# ESP32-C6 register map
Vendor: ESPRESSIF SYSTEMS (SHANGHAI) CO., LTD.; Series: ESP32 C-Series; File version: 2
CPU: RV32IMC r0p0, little endian, no MPU, no FPU, 4 interrupt priority bits
Address unit: 32 bits
Registers are 32-bit, read-write, reset 0x0 unless marked. A register's access mark holds for its fields unless they carry their own. Offsets are from the block's base; [hi:lo] are bit positions; {n}, {i} and the like mark numbered series.

## EXTMEM (part 1 of 2) — External Memory
Base 0x600C8000
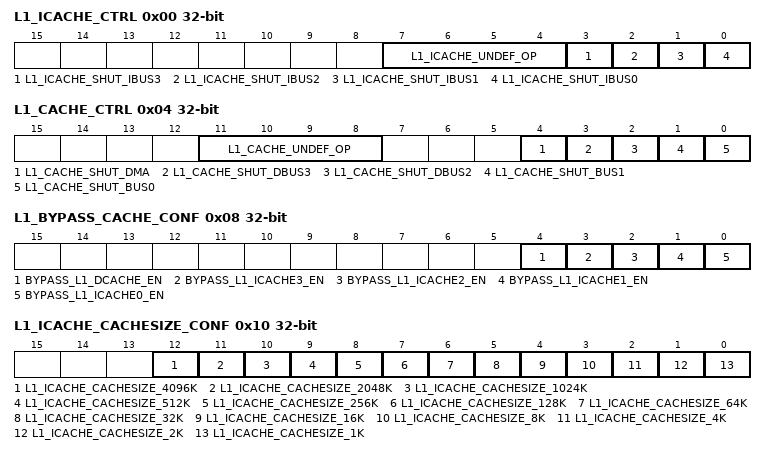
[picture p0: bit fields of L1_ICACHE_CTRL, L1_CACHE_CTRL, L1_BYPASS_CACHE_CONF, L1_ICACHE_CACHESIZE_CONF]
0x00 L1_ICACHE_CTRL ro — L1 instruction Cache(L1-ICache) control register
  [7:4] L1_ICACHE_UNDEF_OP — Reserved
  [3] L1_ICACHE_SHUT_IBUS3 — Reserved
  [2] L1_ICACHE_SHUT_IBUS2 — Reserved
  [1] L1_ICACHE_SHUT_IBUS1 — The bit is used to disable core1 ibus access L1-ICache, 0: enable, 1: disable
  [0] L1_ICACHE_SHUT_IBUS0 — The bit is used to disable core0 ibus access L1-ICache, 0: enable, 1: disable
0x04 L1_CACHE_CTRL access per field — L1 data Cache(L1-Cache) control register
  [11:8] L1_CACHE_UNDEF_OP rw — Reserved
  [4] L1_CACHE_SHUT_DMA ro — The bit is used to disable DMA access L1-Cache, 0: enable, 1: disable
  [3] L1_CACHE_SHUT_DBUS3 ro — Reserved
  [2] L1_CACHE_SHUT_DBUS2 ro — Reserved
  [1] L1_CACHE_SHUT_BUS1 rw — The bit is used to disable core1 dbus access L1-Cache, 0: enable, 1: disable
  [0] L1_CACHE_SHUT_BUS0 rw — The bit is used to disable core0 dbus access L1-Cache, 0: enable, 1: disable
0x08 L1_BYPASS_CACHE_CONF ro — Bypass Cache configure register
  [4] BYPASS_L1_DCACHE_EN — The bit is used to enable bypass L1-DCache. 0: disable bypass, 1: enable bypass.
  [3] BYPASS_L1_ICACHE3_EN — Reserved
  [2] BYPASS_L1_ICACHE2_EN — Reserved
  [1] BYPASS_L1_ICACHE1_EN — The bit is used to enable bypass L1-ICache1. 0: disable bypass, 1: enable bypass.
  [0] BYPASS_L1_ICACHE0_EN — The bit is used to enable bypass L1-ICache0. 0: disable bypass, 1: enable bypass.
0x0C L1_CACHE_ATOMIC_CONF ro — L1 Cache atomic feature configure register
  [0] L1_CACHE_ATOMIC_EN — The bit is used to enable atomic feature on L1-Cache when multiple cores access L1-Cache. 1: disable, 1: enable.
0x10 L1_ICACHE_CACHESIZE_CONF ro — L1 instruction Cache CacheSize mode configure register
  [12] L1_ICACHE_CACHESIZE_4096K — The field is used to configure cachesize of L1-ICache as 4096k bytes. This field and all other fields within this register is onehot.
  [11] L1_ICACHE_CACHESIZE_2048K — The field is used to configure cachesize of L1-ICache as 2048k bytes. This field and all other fields within this register is onehot.
  [10] L1_ICACHE_CACHESIZE_1024K — The field is used to configure cachesize of L1-ICache as 1024k bytes. This field and all other fields within this register is onehot.
  [9] L1_ICACHE_CACHESIZE_512K — The field is used to configure cachesize of L1-ICache as 512k bytes. This field and all other fields within this register is onehot.
  [8] L1_ICACHE_CACHESIZE_256K — The field is used to configure cachesize of L1-ICache as 256k bytes. This field and all other fields within this register is onehot.
  [7] L1_ICACHE_CACHESIZE_128K — The field is used to configure cachesize of L1-ICache as 128k bytes. This field and all other fields within this register is onehot.
  [6] L1_ICACHE_CACHESIZE_64K — The field is used to configure cachesize of L1-ICache as 64k bytes. This field and all other fields within this register is onehot.
  [5] L1_ICACHE_CACHESIZE_32K — The field is used to configure cachesize of L1-ICache as 32k bytes. This field and all other fields within this register is onehot.
  [4] L1_ICACHE_CACHESIZE_16K — The field is used to configure cachesize of L1-ICache as 16k bytes. This field and all other fields within this register is onehot.
  [3] L1_ICACHE_CACHESIZE_8K — The field is used to configure cachesize of L1-ICache as 8k bytes. This field and all other fields within this register is onehot.
  [2] L1_ICACHE_CACHESIZE_4K — The field is used to configure cachesize of L1-ICache as 4k bytes. This field and all other fields within this register is onehot.
  [1] L1_ICACHE_CACHESIZE_2K — The field is used to configure cachesize of L1-ICache as 2k bytes. This field and all other fields within this register is onehot.
  [0] L1_ICACHE_CACHESIZE_1K — The field is used to configure cachesize of L1-ICache as 1k bytes. This field and all other fields within this register is onehot.
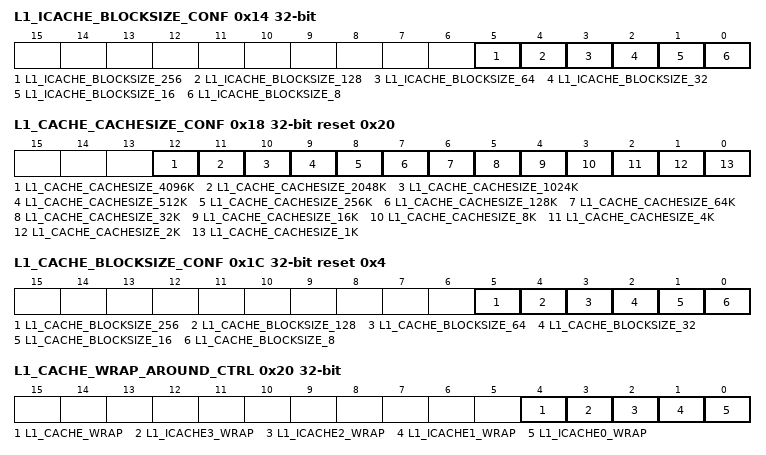
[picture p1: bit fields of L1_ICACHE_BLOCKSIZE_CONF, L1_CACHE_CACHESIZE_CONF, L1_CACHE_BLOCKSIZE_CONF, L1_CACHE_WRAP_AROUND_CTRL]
0x14 L1_ICACHE_BLOCKSIZE_CONF ro — L1 instruction Cache BlockSize mode configure register
  [5] L1_ICACHE_BLOCKSIZE_256 — The field is used to configureblocksize of L1-ICache as 256 bytes. This field and all other fields within this register is onehot.
  [4] L1_ICACHE_BLOCKSIZE_128 — The field is used to configureblocksize of L1-ICache as 128 bytes. This field and all other fields within this register is onehot.
  [3] L1_ICACHE_BLOCKSIZE_64 — The field is used to configureblocksize of L1-ICache as 64 bytes. This field and all other fields within this register is onehot.
  [2] L1_ICACHE_BLOCKSIZE_32 — The field is used to configureblocksize of L1-ICache as 32 bytes. This field and all other fields within this register is onehot.
  [1] L1_ICACHE_BLOCKSIZE_16 — The field is used to configureblocksize of L1-ICache as 16 bytes. This field and all other fields within this register is onehot.
  [0] L1_ICACHE_BLOCKSIZE_8 — The field is used to configureblocksize of L1-ICache as 8 bytes. This field and all other fields within this register is onehot.
0x18 L1_CACHE_CACHESIZE_CONF ro reset 0x20 — L1 data Cache CacheSize mode configure register
  [12] L1_CACHE_CACHESIZE_4096K — The field is used to configure cachesize of L1-Cache as 4096k bytes. This field and all other fields within this register is onehot.
  [11] L1_CACHE_CACHESIZE_2048K — The field is used to configure cachesize of L1-Cache as 2048k bytes. This field and all other fields within this register is onehot.
  [10] L1_CACHE_CACHESIZE_1024K — The field is used to configure cachesize of L1-Cache as 1024k bytes. This field and all other fields within this register is onehot.
  [9] L1_CACHE_CACHESIZE_512K — The field is used to configure cachesize of L1-Cache as 512k bytes. This field and all other fields within this register is onehot.
  [8] L1_CACHE_CACHESIZE_256K — The field is used to configure cachesize of L1-Cache as 256k bytes. This field and all other fields within this register is onehot.
  [7] L1_CACHE_CACHESIZE_128K — The field is used to configure cachesize of L1-Cache as 128k bytes. This field and all other fields within this register is onehot.
  [6] L1_CACHE_CACHESIZE_64K — The field is used to configure cachesize of L1-Cache as 64k bytes. This field and all other fields within this register is onehot.
  [5] L1_CACHE_CACHESIZE_32K — The field is used to configure cachesize of L1-Cache as 32k bytes. This field and all other fields within this register is onehot.
  [4] L1_CACHE_CACHESIZE_16K — The field is used to configure cachesize of L1-Cache as 16k bytes. This field and all other fields within this register is onehot.
  [3] L1_CACHE_CACHESIZE_8K — The field is used to configure cachesize of L1-Cache as 8k bytes. This field and all other fields within this register is onehot.
  [2] L1_CACHE_CACHESIZE_4K — The field is used to configure cachesize of L1-Cache as 4k bytes. This field and all other fields within this register is onehot.
  [1] L1_CACHE_CACHESIZE_2K — The field is used to configure cachesize of L1-Cache as 2k bytes. This field and all other fields within this register is onehot.
  [0] L1_CACHE_CACHESIZE_1K — The field is used to configure cachesize of L1-Cache as 1k bytes. This field and all other fields within this register is onehot.
0x1C L1_CACHE_BLOCKSIZE_CONF ro reset 0x4 — L1 data Cache BlockSize mode configure register
  [5] L1_CACHE_BLOCKSIZE_256 — The field is used to configureblocksize of L1-DCache as 256 bytes. This field and all other fields within this register is onehot.
  [4] L1_CACHE_BLOCKSIZE_128 — The field is used to configureblocksize of L1-DCache as 128 bytes. This field and all other fields within this register is onehot.
  [3] L1_CACHE_BLOCKSIZE_64 — The field is used to configureblocksize of L1-DCache as 64 bytes. This field and all other fields within this register is onehot.
  [2] L1_CACHE_BLOCKSIZE_32 — The field is used to configureblocksize of L1-DCache as 32 bytes. This field and all other fields within this register is onehot.
  [1] L1_CACHE_BLOCKSIZE_16 — The field is used to configureblocksize of L1-DCache as 16 bytes. This field and all other fields within this register is onehot.
  [0] L1_CACHE_BLOCKSIZE_8 — The field is used to configureblocksize of L1-DCache as 8 bytes. This field and all other fields within this register is onehot.
0x20 L1_CACHE_WRAP_AROUND_CTRL access per field — Cache wrap around control register
  [4] L1_CACHE_WRAP rw — Set this bit as 1 to enable L1-DCache wrap around mode.
  [3] L1_ICACHE3_WRAP ro — Reserved
  [2] L1_ICACHE2_WRAP ro — Reserved
  [1] L1_ICACHE1_WRAP ro — Set this bit as 1 to enable L1-ICache1 wrap around mode.
  [0] L1_ICACHE0_WRAP ro — Set this bit as 1 to enable L1-ICache0 wrap around mode.
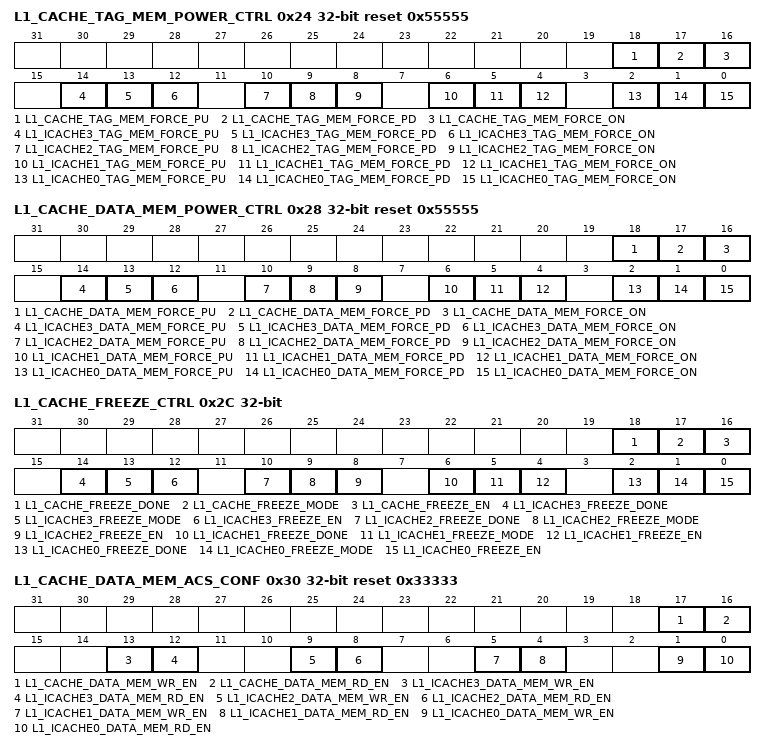
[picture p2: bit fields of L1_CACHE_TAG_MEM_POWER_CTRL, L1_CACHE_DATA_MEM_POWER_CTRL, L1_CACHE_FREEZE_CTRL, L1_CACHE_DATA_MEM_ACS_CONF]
0x24 L1_CACHE_TAG_MEM_POWER_CTRL access per field reset 0x55555 — Cache tag memory power control register
  [18] L1_CACHE_TAG_MEM_FORCE_PU rw — The bit is used to power L1-Cache tag memory up. 0: follow rtc_lslp, 1: power up
  [17] L1_CACHE_TAG_MEM_FORCE_PD rw — The bit is used to power L1-Cache tag memory down. 0: follow rtc_lslp, 1: power down
  [16] L1_CACHE_TAG_MEM_FORCE_ON rw — The bit is used to close clock gating of L1-Cache tag memory. 1: close gating, 0: open clock gating.
  [14] L1_ICACHE3_TAG_MEM_FORCE_PU ro — Reserved
  [13] L1_ICACHE3_TAG_MEM_FORCE_PD ro — Reserved
  [12] L1_ICACHE3_TAG_MEM_FORCE_ON ro — Reserved
  [10] L1_ICACHE2_TAG_MEM_FORCE_PU ro — Reserved
  [9] L1_ICACHE2_TAG_MEM_FORCE_PD ro — Reserved
  [8] L1_ICACHE2_TAG_MEM_FORCE_ON ro — Reserved
  [6] L1_ICACHE1_TAG_MEM_FORCE_PU ro — The bit is used to power L1-ICache1 tag memory up. 0: follow rtc_lslp, 1: power up
  [5] L1_ICACHE1_TAG_MEM_FORCE_PD ro — The bit is used to power L1-ICache1 tag memory down. 0: follow rtc_lslp, 1: power down
  [4] L1_ICACHE1_TAG_MEM_FORCE_ON ro — The bit is used to close clock gating of L1-ICache1 tag memory. 1: close gating, 0: open clock gating.
  [2] L1_ICACHE0_TAG_MEM_FORCE_PU ro — The bit is used to power L1-ICache0 tag memory up. 0: follow rtc_lslp, 1: power up
  [1] L1_ICACHE0_TAG_MEM_FORCE_PD ro — The bit is used to power L1-ICache0 tag memory down. 0: follow rtc_lslp, 1: power down
  [0] L1_ICACHE0_TAG_MEM_FORCE_ON ro — The bit is used to close clock gating of L1-ICache0 tag memory. 1: close gating, 0: open clock gating.
0x28 L1_CACHE_DATA_MEM_POWER_CTRL access per field reset 0x55555 — Cache data memory power control register
  [18] L1_CACHE_DATA_MEM_FORCE_PU rw — The bit is used to power L1-Cache data memory up. 0: follow rtc_lslp, 1: power up
  [17] L1_CACHE_DATA_MEM_FORCE_PD rw — The bit is used to power L1-Cache data memory down. 0: follow rtc_lslp, 1: power down
  [16] L1_CACHE_DATA_MEM_FORCE_ON rw — The bit is used to close clock gating of L1-Cache data memory. 1: close gating, 0: open clock gating.
  [14] L1_ICACHE3_DATA_MEM_FORCE_PU ro — Reserved
  [13] L1_ICACHE3_DATA_MEM_FORCE_PD ro — Reserved
  [12] L1_ICACHE3_DATA_MEM_FORCE_ON ro — Reserved
  [10] L1_ICACHE2_DATA_MEM_FORCE_PU ro — Reserved
  [9] L1_ICACHE2_DATA_MEM_FORCE_PD ro — Reserved
  [8] L1_ICACHE2_DATA_MEM_FORCE_ON ro — Reserved
  [6] L1_ICACHE1_DATA_MEM_FORCE_PU ro — The bit is used to power L1-ICache1 data memory up. 0: follow rtc_lslp, 1: power up
  [5] L1_ICACHE1_DATA_MEM_FORCE_PD ro — The bit is used to power L1-ICache1 data memory down. 0: follow rtc_lslp, 1: power down
  [4] L1_ICACHE1_DATA_MEM_FORCE_ON ro — The bit is used to close clock gating of L1-ICache1 data memory. 1: close gating, 0: open clock gating.
  [2] L1_ICACHE0_DATA_MEM_FORCE_PU ro — The bit is used to power L1-ICache0 data memory up. 0: follow rtc_lslp, 1: power up
  [1] L1_ICACHE0_DATA_MEM_FORCE_PD ro — The bit is used to power L1-ICache0 data memory down. 0: follow rtc_lslp, 1: power down
  [0] L1_ICACHE0_DATA_MEM_FORCE_ON ro — The bit is used to close clock gating of L1-ICache0 data memory. 1: close gating, 0: open clock gating.
0x2C L1_CACHE_FREEZE_CTRL access per field — Cache Freeze control register
  [18] L1_CACHE_FREEZE_DONE ro — The bit is used to indicate whether freeze operation on L1-Cache is finished or not. 0: not finished. 1: finished.
  [17] L1_CACHE_FREEZE_MODE rw — The bit is used to configure mode of freeze operation L1-Cache. 0: a miss-access will not stuck. 1: a miss-access will stuck.
  [16] L1_CACHE_FREEZE_EN rw — The bit is used to enable freeze operation on L1-Cache. It can be cleared by software.
  [14] L1_ICACHE3_FREEZE_DONE ro — Reserved
  [13] L1_ICACHE3_FREEZE_MODE ro — Reserved
  [12] L1_ICACHE3_FREEZE_EN ro — Reserved
  [10] L1_ICACHE2_FREEZE_DONE ro — Reserved
  [9] L1_ICACHE2_FREEZE_MODE ro — Reserved
  [8] L1_ICACHE2_FREEZE_EN ro — Reserved
  [6] L1_ICACHE1_FREEZE_DONE ro — The bit is used to indicate whether freeze operation on L1-ICache1 is finished or not. 0: not finished. 1: finished.
  [5] L1_ICACHE1_FREEZE_MODE ro — The bit is used to configure mode of freeze operation L1-ICache1. 0: a miss-access will not stuck. 1: a miss-access will stuck.
  [4] L1_ICACHE1_FREEZE_EN ro — The bit is used to enable freeze operation on L1-ICache1. It can be cleared by software.
  [2] L1_ICACHE0_FREEZE_DONE ro — The bit is used to indicate whether freeze operation on L1-ICache0 is finished or not. 0: not finished. 1: finished.
  [1] L1_ICACHE0_FREEZE_MODE ro — The bit is used to configure mode of freeze operation L1-ICache0. 0: a miss-access will not stuck. 1: a miss-access will stuck.
  [0] L1_ICACHE0_FREEZE_EN ro — The bit is used to enable freeze operation on L1-ICache0. It can be cleared by software.
0x30 L1_CACHE_DATA_MEM_ACS_CONF access per field reset 0x33333 — Cache data memory access configure register
  [17] L1_CACHE_DATA_MEM_WR_EN rw — The bit is used to enable config-bus write L1-Cache data memoryory. 0: disable, 1: enable.
  [16] L1_CACHE_DATA_MEM_RD_EN rw — The bit is used to enable config-bus read L1-Cache data memoryory. 0: disable, 1: enable.
  [13] L1_ICACHE3_DATA_MEM_WR_EN ro — Reserved
  [12] L1_ICACHE3_DATA_MEM_RD_EN ro — Reserved
  [9] L1_ICACHE2_DATA_MEM_WR_EN ro — Reserved
  [8] L1_ICACHE2_DATA_MEM_RD_EN ro — Reserved
  [5] L1_ICACHE1_DATA_MEM_WR_EN ro — The bit is used to enable config-bus write L1-ICache1 data memoryory. 0: disable, 1: enable.
  [4] L1_ICACHE1_DATA_MEM_RD_EN ro — The bit is used to enable config-bus read L1-ICache1 data memoryory. 0: disable, 1: enable.
  [1] L1_ICACHE0_DATA_MEM_WR_EN ro — The bit is used to enable config-bus write L1-ICache0 data memoryory. 0: disable, 1: enable.
  [0] L1_ICACHE0_DATA_MEM_RD_EN ro — The bit is used to enable config-bus read L1-ICache0 data memoryory. 0: disable, 1: enable.
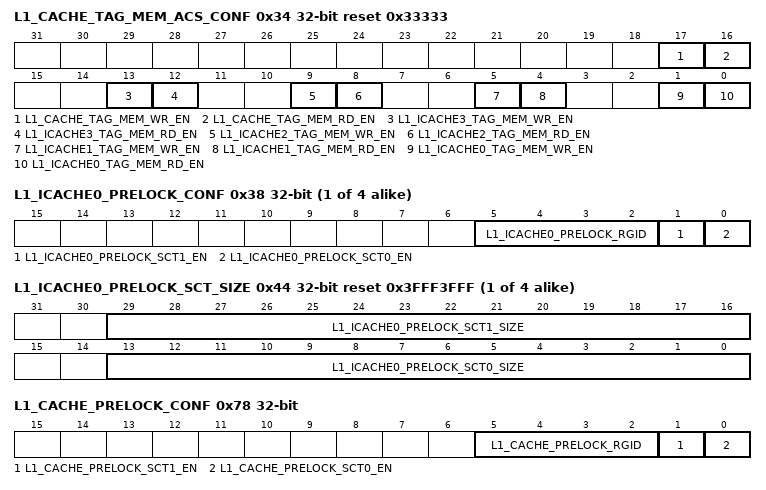
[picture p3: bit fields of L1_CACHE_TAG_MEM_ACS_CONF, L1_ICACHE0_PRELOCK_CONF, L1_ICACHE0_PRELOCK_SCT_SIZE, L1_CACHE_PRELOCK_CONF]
0x34 L1_CACHE_TAG_MEM_ACS_CONF access per field reset 0x33333 — Cache tag memory access configure register
  [17] L1_CACHE_TAG_MEM_WR_EN rw — The bit is used to enable config-bus write L1-Cache tag memoryory. 0: disable, 1: enable.
  [16] L1_CACHE_TAG_MEM_RD_EN rw — The bit is used to enable config-bus read L1-Cache tag memoryory. 0: disable, 1: enable.
  [13] L1_ICACHE3_TAG_MEM_WR_EN ro — Reserved
  [12] L1_ICACHE3_TAG_MEM_RD_EN ro — Reserved
  [9] L1_ICACHE2_TAG_MEM_WR_EN ro — Reserved
  [8] L1_ICACHE2_TAG_MEM_RD_EN ro — Reserved
  [5] L1_ICACHE1_TAG_MEM_WR_EN ro — The bit is used to enable config-bus write L1-ICache1 tag memoryory. 0: disable, 1: enable.
  [4] L1_ICACHE1_TAG_MEM_RD_EN ro — The bit is used to enable config-bus read L1-ICache1 tag memoryory. 0: disable, 1: enable.
  [1] L1_ICACHE0_TAG_MEM_WR_EN ro — The bit is used to enable config-bus write L1-ICache0 tag memoryory. 0: disable, 1: enable.
  [0] L1_ICACHE0_TAG_MEM_RD_EN ro — The bit is used to enable config-bus read L1-ICache0 tag memoryory. 0: disable, 1: enable.
{0x38+0x10*i} L1_ICACHE{i}_PRELOCK_CONF ro (i=0..3) — L1 instruction Cache {i} prelock configure register
  [5:2] L1_ICACHE{i}_PRELOCK_RGID — The bit is used to set the gid of l1 icache{i} prelock.
  [1] L1_ICACHE{i}_PRELOCK_SCT1_EN — The bit is used to enable the second section of prelock function on L1-ICache{i}.
  [0] L1_ICACHE{i}_PRELOCK_SCT0_EN — The bit is used to enable the first section of prelock function on L1-ICache{i}.
{0x3C+0x10*i} L1_ICACHE{i}_PRELOCK_SCT0_ADDR ro (i=0..3) — L1 instruction Cache {i} prelock section0 address configure register
  [31:0] L1_ICACHE{i}_PRELOCK_SCT0_ADDR — Those bits are used to configure the start virtual address of the first section of prelock on L1-ICache{i}, which should be used together with L1_ICACHE{i}_PRELOCK_SCT0_SIZE_REG
{0x40+0x10*i} L1_ICACHE{i}_PRELOCK_SCT1_ADDR ro (i=0..3) — L1 instruction Cache {i} prelock section1 address configure register
  [31:0] L1_ICACHE{i}_PRELOCK_SCT1_ADDR — Those bits are used to configure the start virtual address of the second section of prelock on L1-ICache{i}, which should be used together with L1_ICACHE{i}_PRELOCK_SCT1_SIZE_REG
{0x44+0x10*i} L1_ICACHE{i}_PRELOCK_SCT_SIZE ro reset 0x3FFF3FFF (i=0..3) — L1 instruction Cache {i} prelock section size configure register
  [29:16] L1_ICACHE{i}_PRELOCK_SCT1_SIZE — Those bits are used to configure the size of the second section of prelock on L1-ICache{i}, which should be used together with L1_ICACHE{i}_PRELOCK_SCT1_ADDR_REG
  [13:0] L1_ICACHE{i}_PRELOCK_SCT0_SIZE — Those bits are used to configure the size of the first section of prelock on L1-ICache{i}, which should be used together with L1_ICACHE{i}_PRELOCK_SCT0_ADDR_REG
0x78 L1_CACHE_PRELOCK_CONF access per field — L1 Cache prelock configure register
  [5:2] L1_CACHE_PRELOCK_RGID ro — The bit is used to set the gid of l1 cache prelock.
  [1] L1_CACHE_PRELOCK_SCT1_EN rw — The bit is used to enable the second section of prelock function on L1-Cache.
  [0] L1_CACHE_PRELOCK_SCT0_EN rw — The bit is used to enable the first section of prelock function on L1-Cache.
0x7C L1_CACHE_PRELOCK_SCT0_ADDR — L1 Cache prelock section0 address configure register
  [31:0] L1_CACHE_PRELOCK_SCT0_ADDR — Those bits are used to configure the start virtual address of the first section of prelock on L1-Cache, which should be used together with L1_CACHE_PRELOCK_SCT0_SIZE_REG
0x80 L1_DCACHE_PRELOCK_SCT1_ADDR — L1 Cache prelock section1 address configure register
  [31:0] L1_CACHE_PRELOCK_SCT1_ADDR — Those bits are used to configure the start virtual address of the second section of prelock on L1-Cache, which should be used together with L1_CACHE_PRELOCK_SCT1_SIZE_REG
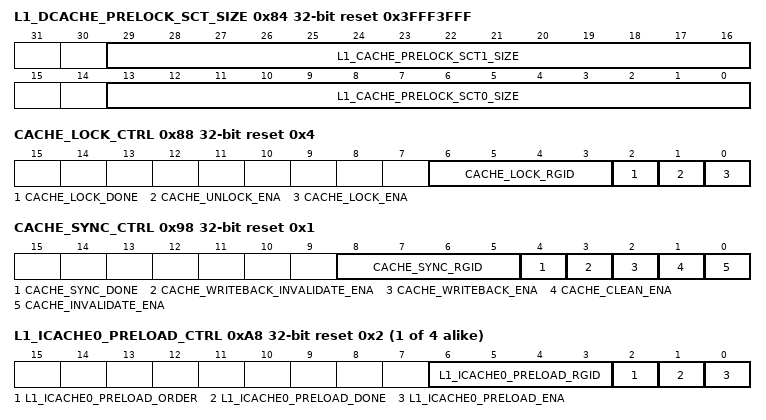
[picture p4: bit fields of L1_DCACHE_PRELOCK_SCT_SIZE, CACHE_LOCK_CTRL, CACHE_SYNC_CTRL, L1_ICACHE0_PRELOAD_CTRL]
0x84 L1_DCACHE_PRELOCK_SCT_SIZE reset 0x3FFF3FFF — L1 Cache prelock section size configure register
  [29:16] L1_CACHE_PRELOCK_SCT1_SIZE — Those bits are used to configure the size of the second section of prelock on L1-Cache, which should be used together with L1_CACHE_PRELOCK_SCT1_ADDR_REG
  [13:0] L1_CACHE_PRELOCK_SCT0_SIZE — Those bits are used to configure the size of the first section of prelock on L1-Cache, which should be used together with L1_CACHE_PRELOCK_SCT0_ADDR_REG
0x88 CACHE_LOCK_CTRL access per field reset 0x4 — Lock-class (manual lock) operation control register
  [6:3] CACHE_LOCK_RGID ro — The bit is used to set the gid of cache lock/unlock.
  [2] CACHE_LOCK_DONE ro — The bit is used to indicate whether unlock/lock operation is finished or not. 0: not finished. 1: finished.
  [1] CACHE_UNLOCK_ENA rw — The bit is used to enable unlock operation. It will be cleared by hardware after unlock operation done
  [0] CACHE_LOCK_ENA rw — The bit is used to enable lock operation. It will be cleared by hardware after lock operation done
0x8C CACHE_LOCK_MAP — Lock (manual lock) map configure register
  [5:0] CACHE_LOCK_MAP — Those bits are used to indicate which caches in the two-level cache structure will apply this lock/unlock operation. [4]: L1-Cache
0x90 CACHE_LOCK_ADDR — Lock (manual lock) address configure register
  [31:0] CACHE_LOCK_ADDR — Those bits are used to configure the start virtual address of the lock/unlock operation, which should be used together with CACHE_LOCK_SIZE_REG
0x94 CACHE_LOCK_SIZE — Lock (manual lock) size configure register
  [15:0] CACHE_LOCK_SIZE — Those bits are used to configure the size of the lock/unlock operation, which should be used together with CACHE_LOCK_ADDR_REG
0x98 CACHE_SYNC_CTRL access per field reset 0x1 — Sync-class operation control register
  [8:5] CACHE_SYNC_RGID ro — The bit is used to set the gid of cache sync operation (invalidate, clean, writeback, writeback_invalidate)
  [4] CACHE_SYNC_DONE ro — The bit is used to indicate whether sync operation (invalidate, clean, writeback, writeback_invalidate) is finished or not. 0: not finished. 1: finished.
  [3] CACHE_WRITEBACK_INVALIDATE_ENA rw — The bit is used to enable writeback-invalidate operation. It will be cleared by hardware after writeback-invalidate operation done. Note that this bit and the other sync-bits (invalidate_ena, clean_ena, writeback_ena) are mutually exclusive, that is, those bits can not be set to 1 at the same time.
  [2] CACHE_WRITEBACK_ENA rw — The bit is used to enable writeback operation. It will be cleared by hardware after writeback operation done. Note that this bit and the other sync-bits (invalidate_ena, clean_ena, writeback_invalidate_ena) are mutually exclusive, that is, those bits can not be set to 1 at the same time.
  [1] CACHE_CLEAN_ENA rw — The bit is used to enable clean operation. It will be cleared by hardware after clean operation done. Note that this bit and the other sync-bits (invalidate_ena, writeback_ena, writeback_invalidate_ena) are mutually exclusive, that is, those bits can not be set to 1 at the same time.
  [0] CACHE_INVALIDATE_ENA rw — The bit is used to enable invalidate operation. It will be cleared by hardware after invalidate operation done. Note that this bit and the other sync-bits (clean_ena, writeback_ena, writeback_invalidate_ena) are mutually exclusive, that is, those bits can not be set to 1 at the same time.
0x9C CACHE_SYNC_MAP reset 0x3F — Sync map configure register
  [5:0] CACHE_SYNC_MAP — Those bits are used to indicate which caches in the two-level cache structure will apply the sync operation. [4]: L1-Cache
0xA0 CACHE_SYNC_ADDR — Sync address configure register
  [31:0] CACHE_SYNC_ADDR — Those bits are used to configure the start virtual address of the sync operation, which should be used together with CACHE_SYNC_SIZE_REG
0xA4 CACHE_SYNC_SIZE — Sync size configure register
  [23:0] CACHE_SYNC_SIZE — Those bits are used to configure the size of the sync operation, which should be used together with CACHE_SYNC_ADDR_REG
{0xA8+0xC*i} L1_ICACHE{i}_PRELOAD_CTRL access per field reset 0x2 (i=0..3) — L1 instruction Cache {i} preload-operation control register
  [6:3] L1_ICACHE{i}_PRELOAD_RGID ro — The bit is used to set the gid of l1 icache{i} preload.
  [2] L1_ICACHE{i}_PRELOAD_ORDER ro — The bit is used to configure the direction of preload operation. 0: ascending, 1: descending.
  [1] L1_ICACHE{i}_PRELOAD_DONE ro — The bit is used to indicate whether preload operation is finished or not. 0: not finished. 1: finished.
  [0] L1_ICACHE{i}_PRELOAD_ENA rw — The bit is used to enable preload operation on L1-ICache{i}. It will be cleared by hardware automatically after preload operation is done.
{0xAC+0xC*i} L1_ICACHE{i}_PRELOAD_ADDR ro (i=0..3) — L1 instruction Cache {i} preload address configure register
  [31:0] L1_ICACHE{i}_PRELOAD_ADDR — Those bits are used to configure the start virtual address of preload on L1-ICache{i}, which should be used together with L1_ICACHE{i}_PRELOAD_SIZE_REG
{0xB0+0xC*i} L1_ICACHE{i}_PRELOAD_SIZE ro (i=0..3) — L1 instruction Cache {i} preload size configure register
  [13:0] L1_ICACHE{i}_PRELOAD_SIZE — Those bits are used to configure the size of the first section of prelock on L1-ICache{i}, which should be used together with L1_ICACHE{i}_PRELOAD_ADDR_REG
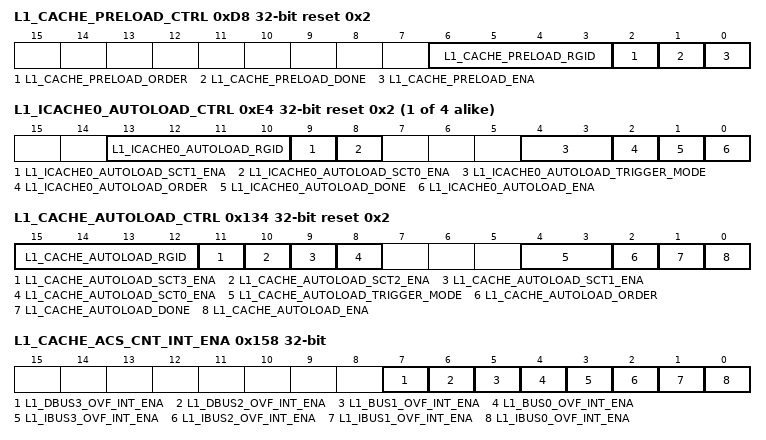
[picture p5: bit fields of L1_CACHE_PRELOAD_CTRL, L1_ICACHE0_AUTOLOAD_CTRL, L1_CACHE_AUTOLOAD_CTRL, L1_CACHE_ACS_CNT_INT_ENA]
0xD8 L1_CACHE_PRELOAD_CTRL access per field reset 0x2 — L1 Cache preload-operation control register
  [6:3] L1_CACHE_PRELOAD_RGID ro — The bit is used to set the gid of l1 cache preload.
  [2] L1_CACHE_PRELOAD_ORDER rw — The bit is used to configure the direction of preload operation. 0: ascending, 1: descending.
  [1] L1_CACHE_PRELOAD_DONE ro — The bit is used to indicate whether preload operation is finished or not. 0: not finished. 1: finished.
  [0] L1_CACHE_PRELOAD_ENA rw — The bit is used to enable preload operation on L1-Cache. It will be cleared by hardware automatically after preload operation is done.
0xDC L1_DCACHE_PRELOAD_ADDR — L1 Cache preload address configure register
  [31:0] L1_CACHE_PRELOAD_ADDR — Those bits are used to configure the start virtual address of preload on L1-Cache, which should be used together with L1_CACHE_PRELOAD_SIZE_REG
0xE0 L1_DCACHE_PRELOAD_SIZE — L1 Cache preload size configure register
  [13:0] L1_CACHE_PRELOAD_SIZE — Those bits are used to configure the size of the first section of prelock on L1-Cache, which should be used together with L1_CACHE_PRELOAD_ADDR_REG
{0xE4+0x14*i} L1_ICACHE{i}_AUTOLOAD_CTRL ro reset 0x2 (i=0..3) — L1 instruction Cache {i} autoload-operation control register
  [13:10] L1_ICACHE{i}_AUTOLOAD_RGID — The bit is used to set the gid of l1 icache{i} autoload.
  [9] L1_ICACHE{i}_AUTOLOAD_SCT1_ENA — The bit is used to enable the second section for autoload operation on L1-ICache{i}.
  [8] L1_ICACHE{i}_AUTOLOAD_SCT0_ENA — The bit is used to enable the first section for autoload operation on L1-ICache{i}.
  [4:3] L1_ICACHE{i}_AUTOLOAD_TRIGGER_MODE — The field is used to configure trigger mode of autoload operation on L1-ICache{i}. 0/3: miss-trigger, 1: hit-trigger, 2: miss-hit-trigger.
  [2] L1_ICACHE{i}_AUTOLOAD_ORDER — The bit is used to configure the direction of autoload operation on L1-ICache{i}. 0: ascending. 1: descending.
  [1] L1_ICACHE{i}_AUTOLOAD_DONE — The bit is used to indicate whether autoload operation on L1-ICache{i} is finished or not. 0: not finished. 1: finished.
  [0] L1_ICACHE{i}_AUTOLOAD_ENA — The bit is used to enable and disable autoload operation on L1-ICache{i}. 1: enable, 0: disable.
{0xE8+0x14*i} L1_ICACHE{i}_AUTOLOAD_SCT0_ADDR ro (i=0..3) — L1 instruction Cache {i} autoload section 0 address configure register
  [31:0] L1_ICACHE{i}_AUTOLOAD_SCT0_ADDR — Those bits are used to configure the start virtual address of the first section for autoload operation on L1-ICache{i}. Note that it should be used together with L1_ICACHE{i}_AUTOLOAD_SCT0_SIZE and L1_ICACHE_AUTOLOAD_SCT0_ENA.
{0xEC+0x14*i} L1_ICACHE{i}_AUTOLOAD_SCT0_SIZE ro (i=0..3) — L1 instruction Cache {i} autoload section 0 size configure register
  [27:0] L1_ICACHE{i}_AUTOLOAD_SCT0_SIZE — Those bits are used to configure the size of the first section for autoload operation on L1-ICache{i}. Note that it should be used together with L1_ICACHE{i}_AUTOLOAD_SCT0_ADDR and L1_ICACHE_AUTOLOAD_SCT0_ENA.
{0xF0+0x14*i} L1_ICACHE{i}_AUTOLOAD_SCT1_ADDR ro (i=0..3) — L1 instruction Cache {i} autoload section 1 address configure register
  [31:0] L1_ICACHE{i}_AUTOLOAD_SCT1_ADDR — Those bits are used to configure the start virtual address of the second section for autoload operation on L1-ICache{i}. Note that it should be used together with L1_ICACHE{i}_AUTOLOAD_SCT1_SIZE and L1_ICACHE_AUTOLOAD_SCT1_ENA.
{0xF4+0x14*i} L1_ICACHE{i}_AUTOLOAD_SCT1_SIZE ro (i=0..2) — L1 instruction Cache {i} autoload section 1 size configure register
  [27:0] L1_ICACHE{i}_AUTOLOAD_SCT1_SIZE — Those bits are used to configure the size of the second section for autoload operation on L1-ICache{i}. Note that it should be used together with L1_ICACHE{i}_AUTOLOAD_SCT1_ADDR and L1_ICACHE_AUTOLOAD_SCT1_ENA.
0x130 L1_ICACHE3_AUTOLOAD_SCT1_SIZE ro — L1 instruction Cache 3 autoload section 1 size configure register
  [27:0] L1_ICACHE3_AUTOLOAD_SCT1_SIZE — Reserved
0x134 L1_CACHE_AUTOLOAD_CTRL access per field reset 0x2 — L1 Cache autoload-operation control register
  [15:12] L1_CACHE_AUTOLOAD_RGID ro — The bit is used to set the gid of l1 cache autoload.
  [11] L1_CACHE_AUTOLOAD_SCT3_ENA ro — The bit is used to enable the fourth section for autoload operation on L1-Cache.
  [10] L1_CACHE_AUTOLOAD_SCT2_ENA ro — The bit is used to enable the third section for autoload operation on L1-Cache.
  [9] L1_CACHE_AUTOLOAD_SCT1_ENA rw — The bit is used to enable the second section for autoload operation on L1-Cache.
  [8] L1_CACHE_AUTOLOAD_SCT0_ENA rw — The bit is used to enable the first section for autoload operation on L1-Cache.
  [4:3] L1_CACHE_AUTOLOAD_TRIGGER_MODE rw — The field is used to configure trigger mode of autoload operation on L1-Cache. 0/3: miss-trigger, 1: hit-trigger, 2: miss-hit-trigger.
  [2] L1_CACHE_AUTOLOAD_ORDER rw — The bit is used to configure the direction of autoload operation on L1-Cache. 0: ascending. 1: descending.
  [1] L1_CACHE_AUTOLOAD_DONE ro — The bit is used to indicate whether autoload operation on L1-Cache is finished or not. 0: not finished. 1: finished.
  [0] L1_CACHE_AUTOLOAD_ENA rw — The bit is used to enable and disable autoload operation on L1-Cache. 1: enable, 0: disable.
0x138 L1_CACHE_AUTOLOAD_SCT0_ADDR — L1 Cache autoload section 0 address configure register
  [31:0] L1_CACHE_AUTOLOAD_SCT0_ADDR — Those bits are used to configure the start virtual address of the first section for autoload operation on L1-Cache. Note that it should be used together with L1_CACHE_AUTOLOAD_SCT0_SIZE and L1_CACHE_AUTOLOAD_SCT0_ENA.
0x13C L1_CACHE_AUTOLOAD_SCT0_SIZE — L1 Cache autoload section 0 size configure register
  [27:0] L1_CACHE_AUTOLOAD_SCT0_SIZE — Those bits are used to configure the size of the first section for autoload operation on L1-Cache. Note that it should be used together with L1_CACHE_AUTOLOAD_SCT0_ADDR and L1_CACHE_AUTOLOAD_SCT0_ENA.
0x140 L1_CACHE_AUTOLOAD_SCT1_ADDR — L1 Cache autoload section 1 address configure register
  [31:0] L1_CACHE_AUTOLOAD_SCT1_ADDR — Those bits are used to configure the start virtual address of the second section for autoload operation on L1-Cache. Note that it should be used together with L1_CACHE_AUTOLOAD_SCT1_SIZE and L1_CACHE_AUTOLOAD_SCT1_ENA.
0x144 L1_CACHE_AUTOLOAD_SCT1_SIZE — L1 Cache autoload section 1 size configure register
  [27:0] L1_CACHE_AUTOLOAD_SCT1_SIZE — Those bits are used to configure the size of the second section for autoload operation on L1-Cache. Note that it should be used together with L1_CACHE_AUTOLOAD_SCT1_ADDR and L1_CACHE_AUTOLOAD_SCT1_ENA.
0x148 L1_CACHE_AUTOLOAD_SCT2_ADDR ro — L1 Cache autoload section 2 address configure register
  [31:0] L1_CACHE_AUTOLOAD_SCT2_ADDR — Those bits are used to configure the start virtual address of the third section for autoload operation on L1-Cache. Note that it should be used together with L1_CACHE_AUTOLOAD_SCT2_SIZE and L1_CACHE_AUTOLOAD_SCT2_ENA.
0x14C L1_CACHE_AUTOLOAD_SCT2_SIZE ro — L1 Cache autoload section 2 size configure register
  [27:0] L1_CACHE_AUTOLOAD_SCT2_SIZE — Those bits are used to configure the size of the third section for autoload operation on L1-Cache. Note that it should be used together with L1_CACHE_AUTOLOAD_SCT2_ADDR and L1_CACHE_AUTOLOAD_SCT2_ENA.
0x150 L1_CACHE_AUTOLOAD_SCT3_ADDR ro — L1 Cache autoload section 1 address configure register
  [31:0] L1_CACHE_AUTOLOAD_SCT3_ADDR — Those bits are used to configure the start virtual address of the fourth section for autoload operation on L1-Cache. Note that it should be used together with L1_CACHE_AUTOLOAD_SCT3_SIZE and L1_CACHE_AUTOLOAD_SCT3_ENA.
0x154 L1_CACHE_AUTOLOAD_SCT3_SIZE ro — L1 Cache autoload section 1 size configure register
  [27:0] L1_CACHE_AUTOLOAD_SCT3_SIZE — Those bits are used to configure the size of the fourth section for autoload operation on L1-Cache. Note that it should be used together with L1_CACHE_AUTOLOAD_SCT3_ADDR and L1_CACHE_AUTOLOAD_SCT3_ENA.
0x158 L1_CACHE_ACS_CNT_INT_ENA access per field — Cache Access Counter Interrupt enable register
  [7] L1_DBUS3_OVF_INT_ENA ro — Reserved
  [6] L1_DBUS2_OVF_INT_ENA ro — Reserved
  [5] L1_BUS1_OVF_INT_ENA rw — The bit is used to enable interrupt of one of counters overflow that occurs in L1-DCache due to bus1 accesses L1-DCache.
  [4] L1_BUS0_OVF_INT_ENA rw — The bit is used to enable interrupt of one of counters overflow that occurs in L1-DCache due to bus0 accesses L1-DCache.
  [3] L1_IBUS3_OVF_INT_ENA ro — Reserved
  [2] L1_IBUS2_OVF_INT_ENA ro — Reserved
  [1] L1_IBUS1_OVF_INT_ENA ro — The bit is used to enable interrupt of one of counters overflow that occurs in L1-ICache1 due to bus1 accesses L1-ICache1.
  [0] L1_IBUS0_OVF_INT_ENA ro — The bit is used to enable interrupt of one of counters overflow that occurs in L1-ICache0 due to bus0 accesses L1-ICache0.
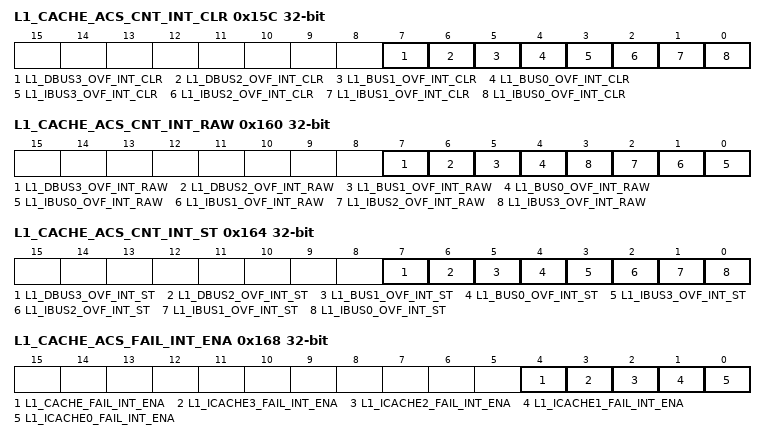
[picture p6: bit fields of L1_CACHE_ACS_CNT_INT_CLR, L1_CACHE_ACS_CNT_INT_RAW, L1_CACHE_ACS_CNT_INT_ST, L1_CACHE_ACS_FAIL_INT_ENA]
0x15C L1_CACHE_ACS_CNT_INT_CLR access per field — Cache Access Counter Interrupt clear register
  [7] L1_DBUS3_OVF_INT_CLR ro — Reserved
  [6] L1_DBUS2_OVF_INT_CLR ro — Reserved
  [5] L1_BUS1_OVF_INT_CLR wo — The bit is used to clear counters overflow interrupt and counters in L1-DCache due to bus1 accesses L1-DCache.
  [4] L1_BUS0_OVF_INT_CLR wo — The bit is used to clear counters overflow interrupt and counters in L1-DCache due to bus0 accesses L1-DCache.
  [3] L1_IBUS3_OVF_INT_CLR ro — Reserved
  [2] L1_IBUS2_OVF_INT_CLR ro — Reserved
  [1] L1_IBUS1_OVF_INT_CLR ro — The bit is used to clear counters overflow interrupt and counters in L1-ICache1 due to bus1 accesses L1-ICache1.
  [0] L1_IBUS0_OVF_INT_CLR ro — The bit is used to clear counters overflow interrupt and counters in L1-ICache0 due to bus0 accesses L1-ICache0.
0x160 L1_CACHE_ACS_CNT_INT_RAW ro — Cache Access Counter Interrupt raw register
  [7] L1_DBUS3_OVF_INT_RAW — The raw bit of the interrupt of one of counters overflow that occurs in L1-DCache due to bus3 accesses L1-DCache.
  [6] L1_DBUS2_OVF_INT_RAW — The raw bit of the interrupt of one of counters overflow that occurs in L1-DCache due to bus2 accesses L1-DCache.
  [5] L1_BUS1_OVF_INT_RAW — The raw bit of the interrupt of one of counters overflow that occurs in L1-DCache due to bus1 accesses L1-DCache.
  [4] L1_BUS0_OVF_INT_RAW — The raw bit of the interrupt of one of counters overflow that occurs in L1-DCache due to bus0 accesses L1-DCache.
  [n] L1_IBUS{n}_OVF_INT_RAW (n=0..3) — The raw bit of the interrupt of one of counters overflow that occurs in L1-ICache{n} due to bus{n} accesses L1-ICache{n}.
0x164 L1_CACHE_ACS_CNT_INT_ST ro — Cache Access Counter Interrupt status register
  [7] L1_DBUS3_OVF_INT_ST — Reserved
  [6] L1_DBUS2_OVF_INT_ST — Reserved
  [5] L1_BUS1_OVF_INT_ST — The bit indicates the interrupt status of one of counters overflow that occurs in L1-DCache due to bus1 accesses L1-DCache.
  [4] L1_BUS0_OVF_INT_ST — The bit indicates the interrupt status of one of counters overflow that occurs in L1-DCache due to bus0 accesses L1-DCache.
  [3] L1_IBUS3_OVF_INT_ST — Reserved
  [2] L1_IBUS2_OVF_INT_ST — Reserved
  [1] L1_IBUS1_OVF_INT_ST — The bit indicates the interrupt status of one of counters overflow that occurs in L1-ICache1 due to bus1 accesses L1-ICache1.
  [0] L1_IBUS0_OVF_INT_ST — The bit indicates the interrupt status of one of counters overflow that occurs in L1-ICache0 due to bus0 accesses L1-ICache0.
0x168 L1_CACHE_ACS_FAIL_INT_ENA access per field — Cache Access Fail Interrupt enable register
  [4] L1_CACHE_FAIL_INT_ENA rw — The bit is used to enable interrupt of access fail that occurs in L1-DCache due to cpu accesses L1-DCache.
  [3] L1_ICACHE3_FAIL_INT_ENA ro — Reserved
  [2] L1_ICACHE2_FAIL_INT_ENA ro — Reserved
  [1] L1_ICACHE1_FAIL_INT_ENA ro — The bit is used to enable interrupt of access fail that occurs in L1-ICache1 due to cpu accesses L1-ICache1.
  [0] L1_ICACHE0_FAIL_INT_ENA ro — The bit is used to enable interrupt of access fail that occurs in L1-ICache0 due to cpu accesses L1-ICache0.
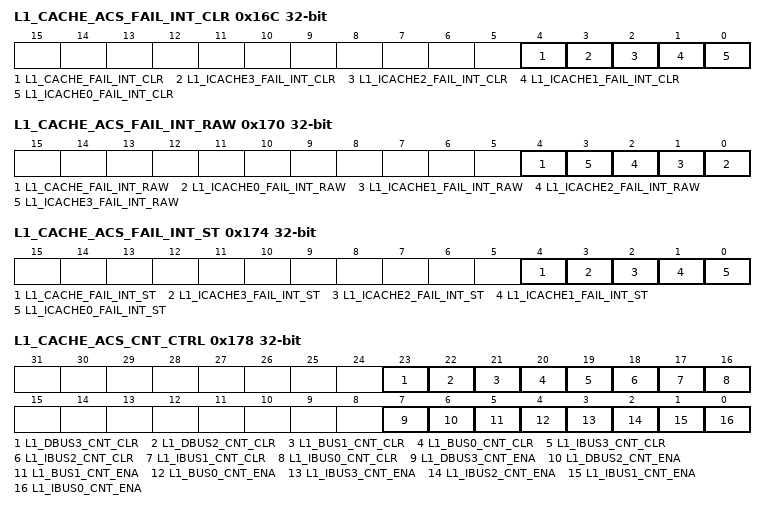
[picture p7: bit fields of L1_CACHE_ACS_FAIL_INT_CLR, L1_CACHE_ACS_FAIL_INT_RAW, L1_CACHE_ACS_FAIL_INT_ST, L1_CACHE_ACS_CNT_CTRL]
0x16C L1_CACHE_ACS_FAIL_INT_CLR access per field — L1-Cache Access Fail Interrupt clear register
  [4] L1_CACHE_FAIL_INT_CLR wo — The bit is used to clear interrupt of access fail that occurs in L1-DCache due to cpu accesses L1-DCache.
  [3] L1_ICACHE3_FAIL_INT_CLR ro — Reserved
  [2] L1_ICACHE2_FAIL_INT_CLR ro — Reserved
  [1] L1_ICACHE1_FAIL_INT_CLR ro — The bit is used to clear interrupt of access fail that occurs in L1-ICache1 due to cpu accesses L1-ICache1.
  [0] L1_ICACHE0_FAIL_INT_CLR ro — The bit is used to clear interrupt of access fail that occurs in L1-ICache0 due to cpu accesses L1-ICache0.
0x170 L1_CACHE_ACS_FAIL_INT_RAW ro — Cache Access Fail Interrupt raw register
  [4] L1_CACHE_FAIL_INT_RAW — The raw bit of the interrupt of access fail that occurs in L1-DCache.
  [n] L1_ICACHE{n}_FAIL_INT_RAW (n=0..3) — The raw bit of the interrupt of access fail that occurs in L1-ICache{n}.
0x174 L1_CACHE_ACS_FAIL_INT_ST ro — Cache Access Fail Interrupt status register
  [4] L1_CACHE_FAIL_INT_ST — The bit indicates the interrupt status of access fail that occurs in L1-DCache due to cpu accesses L1-DCache.
  [3] L1_ICACHE3_FAIL_INT_ST — Reserved
  [2] L1_ICACHE2_FAIL_INT_ST — Reserved
  [1] L1_ICACHE1_FAIL_INT_ST — The bit indicates the interrupt status of access fail that occurs in L1-ICache1 due to cpu accesses L1-ICache.
  [0] L1_ICACHE0_FAIL_INT_ST — The bit indicates the interrupt status of access fail that occurs in L1-ICache0 due to cpu accesses L1-ICache.
0x178 L1_CACHE_ACS_CNT_CTRL access per field — Cache Access Counter enable and clear register
  [23] L1_DBUS3_CNT_CLR ro — Reserved
  [22] L1_DBUS2_CNT_CLR ro — Reserved
  [21] L1_BUS1_CNT_CLR wo — The bit is used to clear dbus1 counter in L1-DCache.
  [20] L1_BUS0_CNT_CLR wo — The bit is used to clear dbus0 counter in L1-DCache.
  [19] L1_IBUS3_CNT_CLR ro — Reserved
  [18] L1_IBUS2_CNT_CLR ro — Reserved
  [17] L1_IBUS1_CNT_CLR ro — The bit is used to clear ibus1 counter in L1-ICache1.
  [16] L1_IBUS0_CNT_CLR ro — The bit is used to clear ibus0 counter in L1-ICache0.
  [7] L1_DBUS3_CNT_ENA ro — Reserved
  [6] L1_DBUS2_CNT_ENA ro — Reserved
  [5] L1_BUS1_CNT_ENA rw — The bit is used to enable dbus1 counter in L1-DCache.
  [4] L1_BUS0_CNT_ENA rw — The bit is used to enable dbus0 counter in L1-DCache.
  [3] L1_IBUS3_CNT_ENA ro — Reserved
  [2] L1_IBUS2_CNT_ENA ro — Reserved
  [1] L1_IBUS1_CNT_ENA ro — The bit is used to enable ibus1 counter in L1-ICache1.
  [0] L1_IBUS0_CNT_ENA ro — The bit is used to enable ibus0 counter in L1-ICache0.
{0x17C+0x10*i} L1_IBUS{i}_ACS_HIT_CNT ro (i=0..3) — L1-ICache bus{i} Hit-Access Counter register
  [31:0] L1_IBUS{i}_HIT_CNT — The register records the number of hits when bus{i} accesses L1-ICache{i}.
{0x180+0x10*i} L1_IBUS{i}_ACS_MISS_CNT ro (i=0..3) — L1-ICache bus{i} Miss-Access Counter register
  [31:0] L1_IBUS{i}_MISS_CNT — The register records the number of missing when bus{i} accesses L1-ICache{i}.
{0x184+0x10*i} L1_IBUS{i}_ACS_CONFLICT_CNT ro (i=0..3) — L1-ICache bus{i} Conflict-Access Counter register
  [31:0] L1_IBUS{i}_CONFLICT_CNT — The register records the number of access-conflicts when bus{i} accesses L1-ICache{i}.
{0x188+0x10*i} L1_IBUS{i}_ACS_NXTLVL_CNT ro (i=0..3) — L1-ICache bus{i} Next-Level-Access Counter register
  [31:0] L1_IBUS{i}_NXTLVL_CNT — The register records the number of times that L1-ICache accesses L2-Cache due to bus{i} accessing L1-ICache{i}.
0x1BC L1_BUS0_ACS_HIT_CNT ro — L1-Cache bus0 Hit-Access Counter register
  [31:0] L1_BUS0_HIT_CNT — The register records the number of hits when bus0 accesses L1-Cache.
0x1C0 L1_BUS0_ACS_MISS_CNT ro — L1-Cache bus0 Miss-Access Counter register
  [31:0] L1_BUS0_MISS_CNT — The register records the number of missing when bus0 accesses L1-Cache.
0x1C4 L1_BUS0_ACS_CONFLICT_CNT ro — L1-Cache bus0 Conflict-Access Counter register
  [31:0] L1_BUS0_CONFLICT_CNT — The register records the number of access-conflicts when bus0 accesses L1-Cache.
